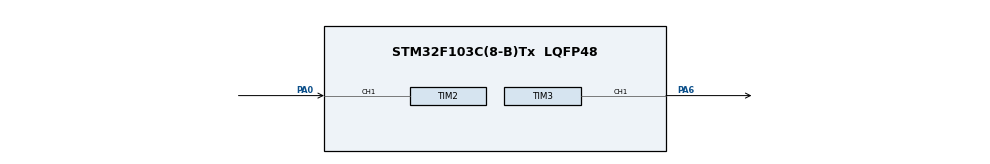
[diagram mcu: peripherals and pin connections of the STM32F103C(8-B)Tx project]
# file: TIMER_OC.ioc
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Mcu.Family=STM32F1
Mcu.Name=STM32F103C(8-B)Tx
Mcu.Package=LQFP48
NVIC.PriorityGroup=NVIC_PRIORITYGROUP_4
NVIC.TIM2_IRQn=true\:0\:0\:false\:false\:true\:true\:true\:true
PA0-WKUP.Signal=S_TIM2_CH1_ETR
PA13.Mode=Serial_Wire
PA13.Signal=SYS_JTMS-SWDIO
PA14.Mode=Serial_Wire
PA14.Signal=SYS_JTCK-SWCLK
PA6.Signal=S_TIM3_CH1
ProjectManager.HeapSize=0x200
ProjectManager.StackSize=0x400
ProjectManager.TargetToolchain=MDK-ARM V5.32
RCC.APB1Freq_Value=8000000
RCC.APB2Freq_Value=8000000
SH.S_TIM2_CH1_ETR.0=TIM2_CH1,Input_Capture1_from_TI1
SH.S_TIM3_CH1.0=TIM3_CH1,Output Compare1 CH1
TIM2.AutoReloadPreload=TIM_AUTORELOAD_PRELOAD_ENABLE
TIM2.Channel-Input_Capture1_from_TI1=TIM_CHANNEL_1
TIM2.Period=7999
TIM2.Prescaler=499
TIM3.AutoReloadPreload=TIM_AUTORELOAD_PRELOAD_ENABLE
TIM3.Channel-Output\ Compare1\ CH1=TIM_CHANNEL_1
TIM3.OCMode_1=TIM_OCMODE_TOGGLE
TIM3.Period=7999
TIM3.Prescaler=499
TIM3.Pulse-Output\ Compare1\ CH1=24
VP_TIM2_VS_ClockSourceINT.Mode=Internal
VP_TIM3_VS_ClockSourceINT.Mode=Internal
board=custom

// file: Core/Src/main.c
/* USER CODE BEGIN Header */
/**
  ******************************************************************************
  * @file           : main.c
  * @brief          : Main program body
  ******************************************************************************
  * @attention
  *
  * Copyright (c) 2022 STMicroelectronics.
  * All rights reserved.
  *
  * This software is licensed under terms that can be found in the LICENSE file
  * in the root directory of this software component.
  * If no LICENSE file comes with this software, it is provided AS-IS.
  *
  ******************************************************************************
  */
/* USER CODE END Header */
#include "main.h"

/* USER CODE BEGIN PTD */
uint16_t u16_captureval=0;
/* USER CODE END PTD */

TIM_HandleTypeDef htim2;
TIM_HandleTypeDef htim3;

void SystemClock_Config(void);
static void MX_GPIO_Init(void);
static void MX_TIM2_Init(void);
static void MX_TIM3_Init(void);

/* USER CODE BEGIN 0 */
void HAL_TIM_IC_CaptureCallback(TIM_HandleTypeDef *htim)
{
  /* Prevent unused argument(s) compilation warning */
  UNUSED(htim);
	if(htim->Instance==TIM2)
	{
		u16_captureval=__HAL_TIM_GET_COMPARE(&htim2,TIM_CHANNEL_1);//doc gia tri capture
		__HAL_TIM_SET_COUNTER(&htim2,0);//xoa counter
	}
  /* NOTE : This function should not be modified, when the callback is needed,
            the HAL_TIM_IC_CaptureCallback could be implemented in the user file
   */
}
/* USER CODE END 0 */

int main(void)
{

  /* MCU Configuration--------------------------------------------------------*/

  /* Reset of all peripherals, Initializes the Flash interface and the Systick. */
  HAL_Init();

  /* Configure the system clock */
  SystemClock_Config();

  /* Initialize all configured peripherals */
  MX_GPIO_Init();
  MX_TIM2_Init();
  MX_TIM3_Init();
  /* USER CODE BEGIN 2 */
	HAL_TIM_IC_Start_IT(&htim2,TIM_CHANNEL_1);//bat IC che do ngat
	HAL_TIM_OC_Start(&htim3,TIM_CHANNEL_1);//bat OC khong ngat
  /* USER CODE END 2 */

  /* Infinite loop */
  while (1)
  {

  }
}

void SystemClock_Config(void)
{
  RCC_OscInitTypeDef RCC_OscInitStruct = {0};
  RCC_ClkInitTypeDef RCC_ClkInitStruct = {0};

  /** Initializes the RCC Oscillators according to the specified parameters
  * in the RCC_OscInitTypeDef structure.
  */
  RCC_OscInitStruct.OscillatorType = RCC_OSCILLATORTYPE_HSI;
  RCC_OscInitStruct.HSIState = RCC_HSI_ON;
  RCC_OscInitStruct.HSICalibrationValue = RCC_HSICALIBRATION_DEFAULT;
  RCC_OscInitStruct.PLL.PLLState = RCC_PLL_NONE;
  if (HAL_RCC_OscConfig(&RCC_OscInitStruct) != HAL_OK)
  {
    Error_Handler();
  }

  /** Initializes the CPU, AHB and APB buses clocks
  */
  RCC_ClkInitStruct.ClockType = RCC_CLOCKTYPE_HCLK|RCC_CLOCKTYPE_SYSCLK
                              |RCC_CLOCKTYPE_PCLK1|RCC_CLOCKTYPE_PCLK2;
  RCC_ClkInitStruct.SYSCLKSource = RCC_SYSCLKSOURCE_HSI;
  RCC_ClkInitStruct.AHBCLKDivider = RCC_SYSCLK_DIV1;
  RCC_ClkInitStruct.APB1CLKDivider = RCC_HCLK_DIV1;
  RCC_ClkInitStruct.APB2CLKDivider = RCC_HCLK_DIV1;

  if (HAL_RCC_ClockConfig(&RCC_ClkInitStruct, FLASH_LATENCY_0) != HAL_OK)
  {
    Error_Handler();
  }
}

static void MX_TIM2_Init(void)
{

  TIM_ClockConfigTypeDef sClockSourceConfig = {0};
  TIM_MasterConfigTypeDef sMasterConfig = {0};
  TIM_IC_InitTypeDef sConfigIC = {0};

  htim2.Instance = TIM2;
  htim2.Init.Prescaler = 499;
  htim2.Init.CounterMode = TIM_COUNTERMODE_UP;
  htim2.Init.Period = 7999;
  htim2.Init.ClockDivision = TIM_CLOCKDIVISION_DIV1;
  htim2.Init.AutoReloadPreload = TIM_AUTORELOAD_PRELOAD_ENABLE;
  if (HAL_TIM_Base_Init(&htim2) != HAL_OK)
  {
    Error_Handler();
  }
  sClockSourceConfig.ClockSource = TIM_CLOCKSOURCE_INTERNAL;
  if (HAL_TIM_ConfigClockSource(&htim2, &sClockSourceConfig) != HAL_OK)
  {
    Error_Handler();
  }
  if (HAL_TIM_IC_Init(&htim2) != HAL_OK)
  {
    Error_Handler();
  }
  sMasterConfig.MasterOutputTrigger = TIM_TRGO_RESET;
  sMasterConfig.MasterSlaveMode = TIM_MASTERSLAVEMODE_DISABLE;
  if (HAL_TIMEx_MasterConfigSynchronization(&htim2, &sMasterConfig) != HAL_OK)
  {
    Error_Handler();
  }
  sConfigIC.ICPolarity = TIM_INPUTCHANNELPOLARITY_RISING;
  sConfigIC.ICSelection = TIM_ICSELECTION_DIRECTTI;
  sConfigIC.ICPrescaler = TIM_ICPSC_DIV1;
  sConfigIC.ICFilter = 0;
  if (HAL_TIM_IC_ConfigChannel(&htim2, &sConfigIC, TIM_CHANNEL_1) != HAL_OK)
  {
    Error_Handler();
  }

}

static void MX_TIM3_Init(void)
{

  TIM_ClockConfigTypeDef sClockSourceConfig = {0};
  TIM_MasterConfigTypeDef sMasterConfig = {0};
  TIM_OC_InitTypeDef sConfigOC = {0};

  htim3.Instance = TIM3;
  htim3.Init.Prescaler = 499;
  htim3.Init.CounterMode = TIM_COUNTERMODE_UP;
  htim3.Init.Period = 7999;
  htim3.Init.ClockDivision = TIM_CLOCKDIVISION_DIV1;
  htim3.Init.AutoReloadPreload = TIM_AUTORELOAD_PRELOAD_ENABLE;
  if (HAL_TIM_Base_Init(&htim3) != HAL_OK)
  {
    Error_Handler();
  }
  sClockSourceConfig.ClockSource = TIM_CLOCKSOURCE_INTERNAL;
  if (HAL_TIM_ConfigClockSource(&htim3, &sClockSourceConfig) != HAL_OK)
  {
    Error_Handler();
  }
  if (HAL_TIM_OC_Init(&htim3) != HAL_OK)
  {
    Error_Handler();
  }
  sMasterConfig.MasterOutputTrigger = TIM_TRGO_RESET;
  sMasterConfig.MasterSlaveMode = TIM_MASTERSLAVEMODE_DISABLE;
  if (HAL_TIMEx_MasterConfigSynchronization(&htim3, &sMasterConfig) != HAL_OK)
  {
    Error_Handler();
  }
  sConfigOC.OCMode = TIM_OCMODE_TOGGLE;
  sConfigOC.Pulse = 24;
  sConfigOC.OCPolarity = TIM_OCPOLARITY_HIGH;
  sConfigOC.OCFastMode = TIM_OCFAST_DISABLE;
  if (HAL_TIM_OC_ConfigChannel(&htim3, &sConfigOC, TIM_CHANNEL_1) != HAL_OK)
  {
    Error_Handler();
  }
  HAL_TIM_MspPostInit(&htim3);

}

static void MX_GPIO_Init(void)
{

  /* GPIO Ports Clock Enable */
  __HAL_RCC_GPIOA_CLK_ENABLE();

}

void Error_Handler(void)
{
  __disable_irq();
  while (1)
  {
  }
}
